# MB9BF31xS register map
File version: 1.7
CPU: 
Registers are 8-bit, read-write, reset 0x0 unless marked. A register's access mark holds for its fields unless they carry their own. Offsets are from the block's base; [hi:lo] are bit positions.

## MFT0 — Multifunction Timer 0
Base 0x40020000
Same registers: MFT1 0x40021000, MFT2 0x40022000
0x00 OCU_OCCP0 16-bit — OCU ch.0 Compare Value Store Register
0x04 OCU_OCCP1 32-bit reset not defined — OCU ch.1 Compare Value Store Register
0x08 OCU_OCCP2 32-bit reset not defined — OCU ch.2 Compare Value Store Register
0x0C OCU_OCCP3 32-bit reset not defined — OCU ch.3 Compare Value Store Register
0x10 OCU_OCCP4 32-bit reset not defined — OCU ch.4 Compare Value Store Register
0x14 OCU_OCCP5 32-bit reset not defined — OCU ch.5 Compare Value Store Register
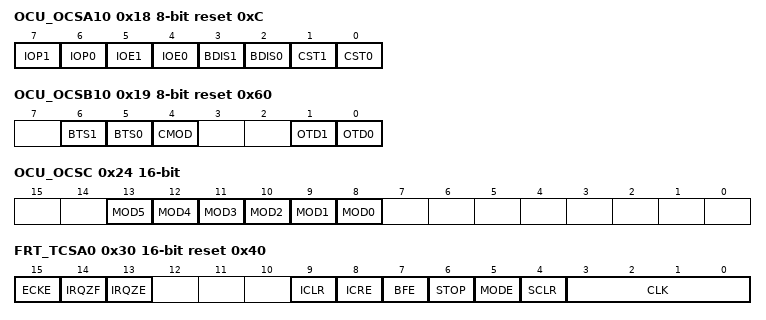
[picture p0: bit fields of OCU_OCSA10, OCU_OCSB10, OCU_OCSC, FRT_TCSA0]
0x18 OCU_OCSA10 reset 0xC — "OCU ch.1,0 Control Register A"
  [7] IOP1 — Indicates that a match has already been detected between FRT's count value and OCCP(1) value at OCU ch.(1).
  [6] IOP0 — Indicates that a match has already been detected between FRT's count value and OCCP(0) value at OCU ch.(0).
  [5] IOE1 — "Generates interrupt, when ""1"" is set to OCSA.IOP1"
  [4] IOE0 — "Generates interrupt, when ""1"" is set to OCSA.IOP0"
  [3] BDIS1 — Disables the buffer function of the OCCP(1) register
  [2] BDIS0 — Disables the buffer function of the OCCP(0) register
  [1] CST1 — Enables the operation of OCU ch.(1)
  [0] CST0 — Enables the operation of OCU ch.(0)
0x19 OCU_OCSB10 reset 0x60 — "OCU ch.1,0 Control Register B"
  [6] BTS1 — Performs buffer transfer of the OCCP(1) register upon Peak value detection by FRT
  [5] BTS0 — Performs buffer transfer of the OCCP(0) register upon Peak value detection by FRT
  [4] CMOD — selects OCU's operation mode in combination with OCSC.MOD0 to MOD5
  [1] OTD1 — Indicates that the RT(1) output pin is in the High-level output state.
  [0] OTD0 — Indicates that the RT(0) output pin is in the High-level output state.
0x1C OCU_OCSA32 32-bit reset not defined — "OCU ch.3,2 Control Register A"
0x1D OCU_OCSB32 32-bit reset not defined — "OCU ch.3,2 Control Register B"
0x20 OCU_OCSA54 32-bit reset not defined — "OCU ch.5,4 Control Register A"
0x21 OCU_OCSB54 32-bit reset not defined — "OCU ch.5,4 Control Register B"
0x24 OCU_OCSC 16-bit — OCU Control Register C
  [13] MOD5 — OCSC.MOD4 and OCSC.MOD5 determine the operation mode of OCU ch.4/ch.5 in combination with OCSB54.CMOD
  [12] MOD4 — OCSC.MOD4 and OCSC.MOD5 determine the operation mode of OCU ch.4/ch.5 in combination with OCSB54.CMOD
  [11] MOD3 — OCSC.MOD2 and OCSC.MOD3 determine the operation mode of OCU ch.2/ch.3 in combination with OCSB32.CMOD
  [10] MOD2 — OCSC.MOD2 and OCSC.MOD3 determine the operation mode of OCU ch.2/ch.3 in combination with OCSB32.CMOD
  [9] MOD1 — OCSC.MOD0 and OCSC.MOD1 determine the operation mode of OCU ch.0/ch.1 in combination with OCSB10.CMOD
  [8] MOD0 — OCSC.MOD0 and OCSC.MOD1 determine the operation mode of OCU ch.0/ch.1 in combination with OCSB10.CMOD
0x28 FRT_TCCP0 16-bit reset 0xFFFF — FRT-ch.0 Cycle Setting Register
0x2C FRT_TCDT0 16-bit — FRT-ch.0 Count Value Register
0x30 FRT_TCSA0 16-bit reset 0x40 — FRT-ch.0 Control Register A
  [15] ECKE — Uses an external input clock (FRCK) as FRT's count clock
  [14] IRQZF — zero interrupt flag
  [13] IRQZE — "Generates interrupt, when ""1"" is set to TCSA.IRQZF"
  [9] ICLR — interrupt flag
  [8] ICRE — "Generates interrupt when ""1"" is set to TCSA.ICLR"
  [7] BFE — Enables TCCP's buffer function
  [6] STOP — Puts FRT in stopping state
  [5] MODE — FRT's count mode
  [4] SCLR wo — FRT operation state initialization request
  [3:0] CLK — FRT clock cycle
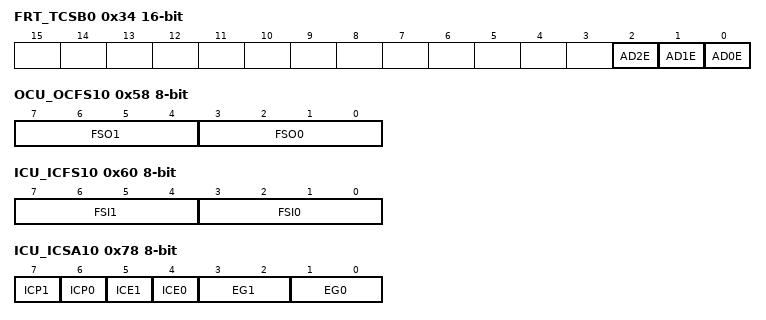
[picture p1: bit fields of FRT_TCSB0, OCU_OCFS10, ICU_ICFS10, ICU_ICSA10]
0x34 FRT_TCSB0 16-bit — FRT-ch.0 Control Register B
  [2] AD2E — Outputs AD conversion start signal to ADCunit2 upon Zero value detection by FRT
  [1] AD1E — Outputs AD conversion start signal to ADCunit1 upon Zero value detection by FRT
  [0] AD0E — Outputs AD conversion start signal to ADCunit0 upon Zero value detection by FRT
0x38 FRT_TCCP1 32-bit reset not defined — FRT-ch.1 Cycle Setting Register
0x3C FRT_TCDT1 32-bit reset not defined — FRT-ch.1 Count Value Register
0x40 FRT_TCSA1 32-bit reset not defined — FRT-ch.1 Control Register A
0x44 FRT_TCSB1 32-bit reset not defined — FRT-ch.1 Control Register B
0x48 FRT_TCCP2 32-bit reset not defined — FRT-ch.2 Cycle Setting Register
0x4C FRT_TCDT2 32-bit reset not defined — FRT-ch.2 Count Value Register
0x50 FRT_TCSA2 32-bit reset not defined — FRT-ch.2 Control Register A
0x54 FRT_TCSB2 32-bit reset not defined — FRT-ch.2 Control Register B
0x58 OCU_OCFS10 — "OCU ch.1,0 Connecting FRT Select Register"
  [7:4] FSO1 — Connects FRT ch.x to OCU ch.1
  [3:0] FSO0 — Connects FRT ch.x to OCU ch.0
0x59 OCU_OCFS32 32-bit reset not defined — "OCU ch.3,2 Connecting FRT Select Register"
0x5C OCU_OCFS54 32-bit reset not defined — "OCU ch.5,4 Connecting FRT Select Register"
0x60 ICU_ICFS10 — "ICU ch.1,0 Connecting FRT Select Register"
  [7:4] FSI1 — Connects FRT ch.x to ICU ch.(1)
  [3:0] FSI0 — Connects FRT ch.x to ICU ch.(0)
0x61 ICU_ICFS32 32-bit reset not defined — "ICU ch.3,2 Connecting FRT Select Register"
0x68 ICU_ICCP0 16-bit ro reset not defined — ICU ch.0 Capture value store register
0x6C ICU_ICCP1 32-bit reset not defined — ICU ch.1 Capture value store register
0x70 ICU_ICCP2 32-bit reset not defined — ICU ch.2 Capture value store register
0x74 ICU_ICCP3 32-bit reset not defined — ICU ch.3 Capture value store register
0x78 ICU_ICSA10 — "ICU ch.1,0 Control Register A"
  [7] ICP1 — Indicates that a valid edge has been detected at ICU ch.(1) and the capture operation has been performed
  [6] ICP0 — Indicates that a valid edge has been detected at ICU ch.(0) and the capture operation has been performed
  [5] ICE1 — "Generates interrupt, when ""1"" is set to ICSA.ICP1."
  [4] ICE0 — "Generates interrupt, when ""1"" is set to ICSA.ICP0."
  [3:2] EG1 — enables/disables the operation of ICU-ch.(1) and selects a valid edge(s)
  [1:0] EG0 — enables/disables the operation of ICU-ch.(0) and selects a valid edge(s)
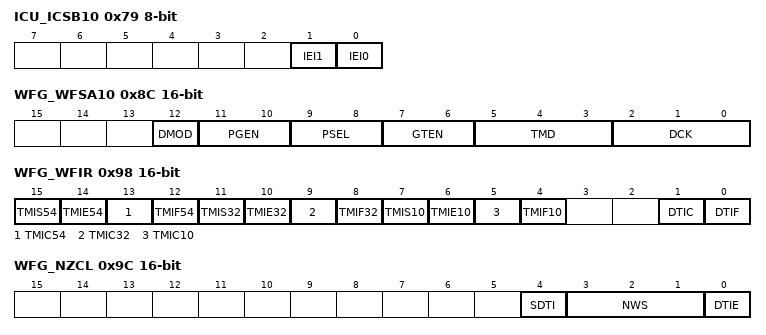
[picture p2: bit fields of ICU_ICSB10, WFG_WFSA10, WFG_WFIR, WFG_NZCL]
0x79 ICU_ICSB10 ro — "ICU ch.1,0 Control Register B"
  [1] IEI1 — indicates the latest valid edge of ICU-ch.(1)
  [0] IEI0 — indicates the latest valid edge of ICU-ch.(0)
0x7C ICU_ICSA32 32-bit reset not defined — "ICU ch.3,2 Control Register A"
0x7D ICU_ICSB32 32-bit reset not defined — "ICU ch.3,2 Control Register B"
0x80 WFG_WFTM10 16-bit — WFG ch.10 Timer Value Register
0x84 WFG_WFTM32 32-bit reset not defined — WFG ch.32 Timer Value Register
0x88 WFG_WFTM54 32-bit reset not defined — WFG ch.54 Timer Value Register
0x8C WFG_WFSA10 16-bit — WFG ch.10 Control Register A
  [12] DMOD — specifies which polarity will be used to output the non-overlap signal
  [11:10] PGEN — specifies how to reflect the CH_PPG signal that is input to each channel of WFG on WFG output
  [9:8] PSEL — the PPG timer unit to be used at each channel of WFG
  [7:6] GTEN — the CH_GATE signal for each channel of WFG
  [5:3] TMD — WFG's operation mode
  [2:0] DCK — clock cycle of the WFG timer
0x90 WFG_WFSA32 32-bit reset not defined — WFG ch.32 Control Register A
0x94 WFG_WFSA54 32-bit reset not defined — WFG ch.54 Control Register A
0x98 WFG_WFIR 16-bit — WFG Interrupt Control Register
  [15] TMIS54 wo — Stops the WFG54 timer
  [14] TMIE54 — Starts the WFG54 timer
  [13] TMIC54 wo — Clears WFIR.TMIF54 and deasserts the WFG54 timer interrupt signal.
  [12] TMIF54 ro — Indicates that WFG54 timer interrupt has been generated.
  [11] TMIS32 wo — Stops the WFG32 timer
  [10] TMIE32 — Starts the WFG32 timer
  [9] TMIC32 wo — Clears WFIR.TMIF32 and deasserts the WFG32 timer interrupt signal.
  [8] TMIF32 ro — Indicates that WFG32 timer interrupt has been generated.
  [7] TMIS10 wo — Stops the WFG10 timer
  [6] TMIE10 — Starts the WFG10 timer
  [5] TMIC10 wo — Clears WFIR.TMIF10 and deasserts the WFG10 timer interrupt signal.
  [4] TMIF10 ro — Indicates that WFG10 timer interrupt has been generated.
  [1] DTIC wo — Clears WFIR.DTIF and deasserts the DTIF interrupt signal.
  [0] DTIF ro — Indicates that DTIF interrupt has been generated.
0x9C WFG_NZCL 16-bit — NZCL Control Register
  [4] SDTI wo — Forcibly generates DTIF interrupt
  [3:1] NWS — noise-canceling width of the noise-canceller for the DTTIX pin
  [0] DTIE — DTIF interrupt enable
0xA0 ADCMP_ACCP0 16-bit — ADCMP ch.0 Compare Value Store Register
0xA4 ADCMP_ACCPDN0 16-bit — ADCMP ch.0 Compare Value Store Register
0xA8 ADCMP_ACCP1 32-bit reset not defined — ADCMP ch.1 Compare Value Store Register
0xAC ADCMP_ACCPDN1 32-bit reset not defined — ADCMP ch.1 Compare Value Store Register
0xB0 ADCMP_ACCP2 32-bit reset not defined — ADCMP ch.2 Compare Value Store Register
0xB4 ADCMP_ACCPDN2 32-bit reset not defined — ADCMP ch.2 Compare Value Store Register
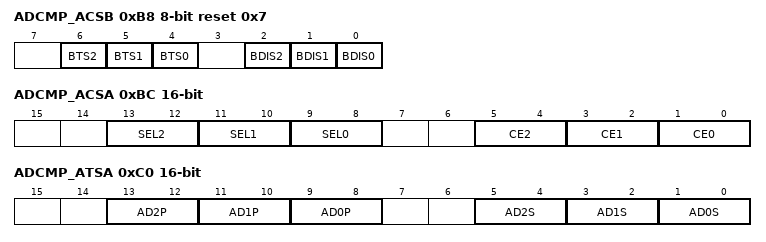
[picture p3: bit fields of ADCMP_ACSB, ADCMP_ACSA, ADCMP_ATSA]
0xB8 ADCMP_ACSB reset 0x7 — ADCMP Control Register B
  [6] BTS2 — Performs buffer transfer of the ACCP2 and ACCPDN2 registers upon Peak value detection by FRT
  [5] BTS1 — Performs buffer transfer of the ACCP1 and ACCPDN1 registers upon Peak value detection by FRT
  [4] BTS0 — Performs buffer transfer of the ACCP0 and ACCPDN0 registers upon Peak value detection by FRT
  [2] BDIS2 — Disables the buffer function of the ACCP2 and ACCPDN2 registers
  [1] BDIS1 — Disables the buffer function of the ACCP1 and ACCPDN1 registers
  [0] BDIS0 — Disables the buffer function of the ACCP0 and ACCPDN0 registers
0xBC ADCMP_ACSA 16-bit — ADCMP Control Register A
  [13:12] SEL2 — which count state FRT should be in to instruct AD conversion to be started at ADCMP-ch.2
  [11:10] SEL1 — which count state FRT should be in to instruct AD conversion to be started at ADCMP-ch.1
  [9:8] SEL0 — which count state FRT should be in to instruct AD conversion to be started at ADCMP-ch.0
  [5:4] CE2 — enable or disable the operation of ADCMP-ch.2 and select the FRT to be connected
  [3:2] CE1 — enable or disable the operation of ADCMP-ch.1 and select the FRT to be connected
  [1:0] CE0 — enable or disable the operation of ADCMP-ch.0 and select the FRT to be connected
0xC0 ADCMP_ATSA 16-bit — ADC Start Trigger Select Register
  [13:12] AD2P — selects the start signal to be used to start priority conversion of ADC unit2
  [11:10] AD1P — selects the start signal to be used to start priority conversion of ADC unit1
  [9:8] AD0P — selects the start signal to be used to start priority conversion of ADC unit0
  [5:4] AD2S — selects the start signal to be used to start the scan conversion of ADC unit2
  [3:2] AD1S — selects the start signal to be used to start the scan conversion of ADC unit1
  [1:0] AD0S — selects the start signal to be used to start the scan conversion of ADC unit0
